AUTOSAR XML (schema 4-2-2)
package /STELLANTIS/EPT/COMSWCs
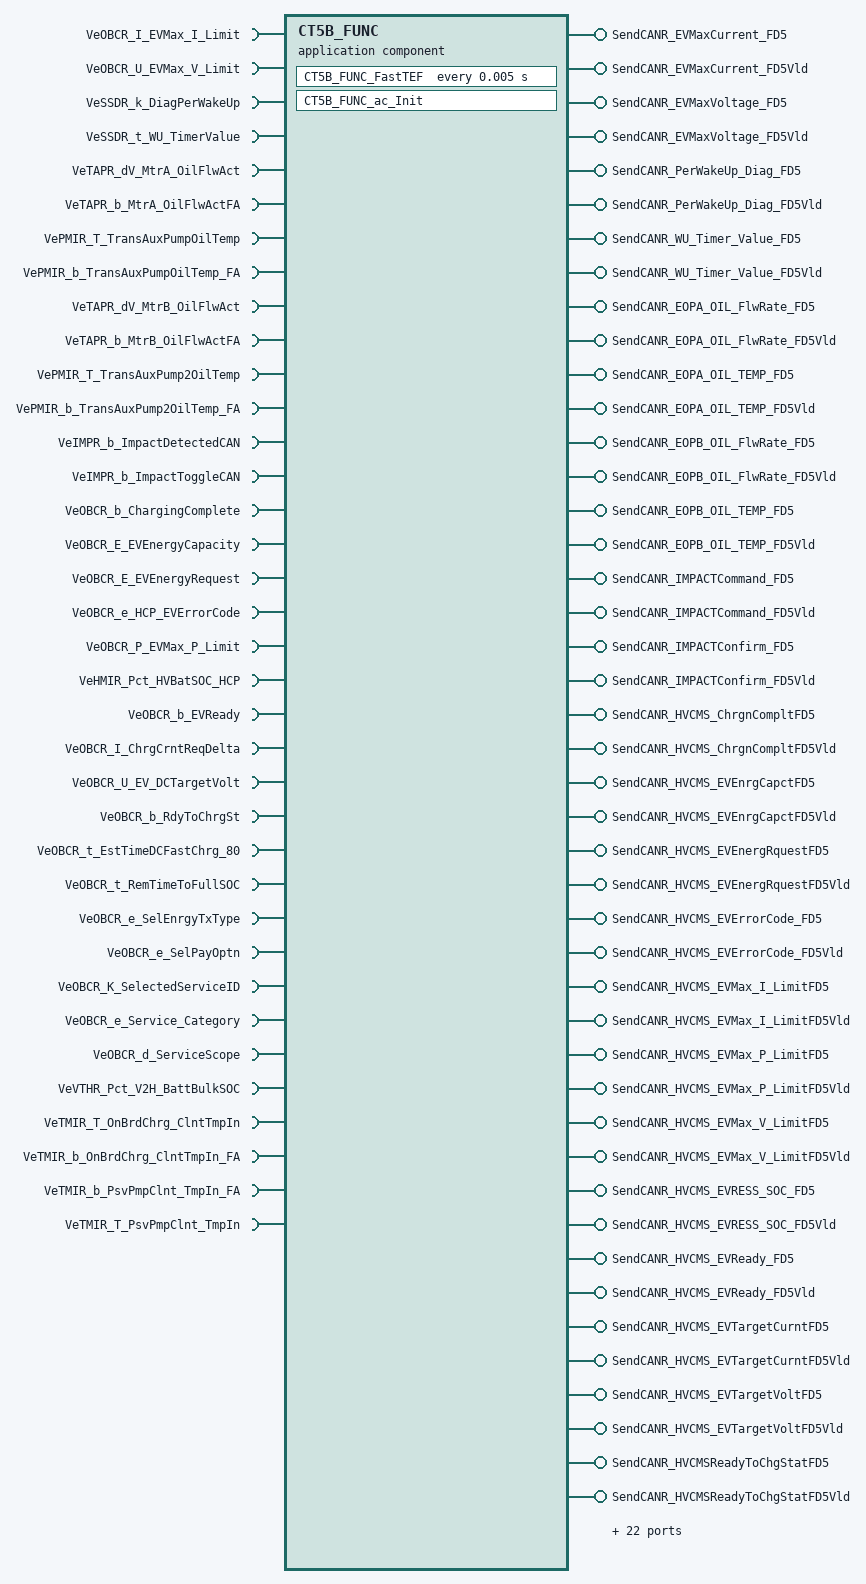
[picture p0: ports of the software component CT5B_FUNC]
  application sw component type CT5B_FUNC
    36 x require port:
      VeOBCR_I_EVMax_I_Limit: nonqueued-receiver-com-spec{data-element=Value, init-value=0}, required-interface=VeOBCR_I_EVMax_I_Limit
      VeOBCR_U_EVMax_V_Limit: nonqueued-receiver-com-spec{data-element=Value, init-value=0}, required-interface=VeOBCR_U_EVMax_V_Limit
      VeSSDR_k_DiagPerWakeUp: nonqueued-receiver-com-spec{data-element=Value, init-value=0}, required-interface=VeSSDR_k_DiagPerWakeUp
      VeSSDR_t_WU_TimerValue: nonqueued-receiver-com-spec{data-element=Value, init-value=0}, required-interface=VeSSDR_t_WU_TimerValue
      VeTAPR_dV_MtrA_OilFlwAct: nonqueued-receiver-com-spec{data-element=Value, init-value=0}, required-interface=VeTAPR_dV_MtrA_OilFlwAct
      VeTAPR_b_MtrA_OilFlwActFA: nonqueued-receiver-com-spec{data-element=Value, init-value=0}, required-interface=VeTAPR_b_MtrA_OilFlwActFA
      VePMIR_T_TransAuxPumpOilTemp: nonqueued-receiver-com-spec{data-element=Value, init-value=0}, required-interface=VePMIR_T_TransAuxPumpOilTemp
      VePMIR_b_TransAuxPumpOilTemp_FA: nonqueued-receiver-com-spec{data-element=Value, init-value=0}, required-interface=VePMIR_b_TransAuxPumpOilTemp_FA
      VeTAPR_dV_MtrB_OilFlwAct: nonqueued-receiver-com-spec{data-element=Value, init-value=0}, required-interface=VeTAPR_dV_MtrB_OilFlwAct
      VeTAPR_b_MtrB_OilFlwActFA: nonqueued-receiver-com-spec{data-element=Value, init-value=0}, required-interface=VeTAPR_b_MtrB_OilFlwActFA
      VePMIR_T_TransAuxPump2OilTemp: nonqueued-receiver-com-spec{data-element=Value, init-value=0}, required-interface=VePMIR_T_TransAuxPump2OilTemp
      VePMIR_b_TransAuxPump2OilTemp_FA: nonqueued-receiver-com-spec{data-element=Value, init-value=0}, required-interface=VePMIR_b_TransAuxPump2OilTemp_FA
      VeIMPR_b_ImpactDetectedCAN: nonqueued-receiver-com-spec{data-element=Value, init-value=0}, required-interface=VeIMPR_b_ImpactDetectedCAN
      VeIMPR_b_ImpactToggleCAN: nonqueued-receiver-com-spec{data-element=Value, init-value=0}, required-interface=VeIMPR_b_ImpactToggleCAN
      VeOBCR_b_ChargingComplete: nonqueued-receiver-com-spec{data-element=Value, init-value=0}, required-interface=VeOBCR_b_ChargingComplete
      VeOBCR_E_EVEnergyCapacity: nonqueued-receiver-com-spec{data-element=Value, init-value=0}, required-interface=VeOBCR_E_EVEnergyCapacity
      VeOBCR_E_EVEnergyRequest: nonqueued-receiver-com-spec{data-element=Value, init-value=0}, required-interface=VeOBCR_E_EVEnergyRequest
      VeOBCR_e_HCP_EVErrorCode: nonqueued-receiver-com-spec{data-element=Value, init-value=0}, required-interface=VeOBCR_e_HCP_EVErrorCode
      VeOBCR_P_EVMax_P_Limit: nonqueued-receiver-com-spec{data-element=Value, init-value=0}, required-interface=VeOBCR_P_EVMax_P_Limit
      VeHMIR_Pct_HVBatSOC_HCP: nonqueued-receiver-com-spec{data-element=Value, init-value=0}, required-interface=VeHMIR_Pct_HVBatSOC_HCP
      VeOBCR_b_EVReady: nonqueued-receiver-com-spec{data-element=Value, init-value=0}, required-interface=VeOBCR_b_EVReady
      VeOBCR_I_ChrgCrntReqDelta: nonqueued-receiver-com-spec{data-element=Value, init-value=0}, required-interface=VeOBCR_I_ChrgCrntReqDelta
      VeOBCR_U_EV_DCTargetVolt: nonqueued-receiver-com-spec{data-element=Value, init-value=0}, required-interface=VeOBCR_U_EV_DCTargetVolt
      VeOBCR_b_RdyToChrgSt: nonqueued-receiver-com-spec{data-element=Value, init-value=0}, required-interface=VeOBCR_b_RdyToChrgSt
      VeOBCR_t_EstTimeDCFastChrg_80: nonqueued-receiver-com-spec{data-element=Value, init-value=0}, required-interface=VeOBCR_t_EstTimeDCFastChrg_80
      VeOBCR_t_RemTimeToFullSOC: nonqueued-receiver-com-spec{data-element=Value, init-value=0}, required-interface=VeOBCR_t_RemTimeToFullSOC
      VeOBCR_e_SelEnrgyTxType: nonqueued-receiver-com-spec{data-element=Value, init-value=0}, required-interface=VeOBCR_e_SelEnrgyTxType
      VeOBCR_e_SelPayOptn: nonqueued-receiver-com-spec{data-element=Value, init-value=CeOBCR_e_NoPaymentSel}, required-interface=VeOBCR_e_SelPayOptn
      VeOBCR_K_SelectedServiceID: nonqueued-receiver-com-spec{data-element=Value, init-value=0}, required-interface=VeOBCR_K_SelectedServiceID
      VeOBCR_e_Service_Category: nonqueued-receiver-com-spec{data-element=Value, init-value=0}, required-interface=VeOBCR_e_Service_Category
      VeOBCR_d_ServiceScope: variation-point={short-label=vpVeOBCR_d_ServiceScope, sw-syscond=1}, nonqueued-receiver-com-spec{data-element=Value, init-value=0}, required-interface=VeOBCR_d_ServiceScope
      VeVTHR_Pct_V2H_BattBulkSOC: variation-point={short-label=vpVeVTHR_Pct_V2H_BattBulkSOC, sw-syscond=1}, nonqueued-receiver-com-spec{data-element=Value, init-value=0}, required-interface=VeVTHR_Pct_V2H_BattBulkSOC
      VeTMIR_T_OnBrdChrg_ClntTmpIn: nonqueued-receiver-com-spec{data-element=Value, init-value=0}, required-interface=VeTMIR_T_OnBrdChrg_ClntTmpIn
      VeTMIR_b_OnBrdChrg_ClntTmpIn_FA: nonqueued-receiver-com-spec{data-element=Value, init-value=0}, required-interface=VeTMIR_b_OnBrdChrg_ClntTmpIn_FA
      VeTMIR_b_PsvPmpClnt_TmpIn_FA: nonqueued-receiver-com-spec{data-element=Value, init-value=0}, required-interface=VeTMIR_b_PsvPmpClnt_TmpIn_FA
      VeTMIR_T_PsvPmpClnt_TmpIn: nonqueued-receiver-com-spec{data-element=Value, init-value=0}, required-interface=VeTMIR_T_PsvPmpClnt_TmpIn
    66 x provide port:
      SendCANR_EVMaxCurrent_FD5: nonqueued-sender-com-spec{data-element=SendCANR_EVMaxCurrent_FD5, init-value=0}, provided-interface=SendCANR_EVMaxCurrent_FD5
      SendCANR_EVMaxCurrent_FD5Vld: nonqueued-sender-com-spec{data-element=SendCANR_EVMaxCurrent_FD5Vld, init-value=0}, provided-interface=SendCANR_EVMaxCurrent_FD5Vld
      SendCANR_EVMaxVoltage_FD5: nonqueued-sender-com-spec{data-element=SendCANR_EVMaxVoltage_FD5, init-value=0}, provided-interface=SendCANR_EVMaxVoltage_FD5
      SendCANR_EVMaxVoltage_FD5Vld: nonqueued-sender-com-spec{data-element=SendCANR_EVMaxVoltage_FD5Vld, init-value=0}, provided-interface=SendCANR_EVMaxVoltage_FD5Vld
      SendCANR_PerWakeUp_Diag_FD5: nonqueued-sender-com-spec{data-element=SendCANR_PerWakeUp_Diag_FD5, init-value=0}, provided-interface=SendCANR_PerWakeUp_Diag_FD5
      SendCANR_PerWakeUp_Diag_FD5Vld: nonqueued-sender-com-spec{data-element=SendCANR_PerWakeUp_Diag_FD5Vld, init-value=0}, provided-interface=SendCANR_PerWakeUp_Diag_FD5Vld
      SendCANR_WU_Timer_Value_FD5: nonqueued-sender-com-spec{data-element=SendCANR_WU_Timer_Value_FD5, init-value=0}, provided-interface=SendCANR_WU_Timer_Value_FD5
      SendCANR_WU_Timer_Value_FD5Vld: nonqueued-sender-com-spec{data-element=SendCANR_WU_Timer_Value_FD5Vld, init-value=0}, provided-interface=SendCANR_WU_Timer_Value_FD5Vld
      SendCANR_EOPA_OIL_FlwRate_FD5: nonqueued-sender-com-spec{data-element=SendCANR_EOPA_OIL_FlwRate_FD5, init-value=0}, provided-interface=SendCANR_EOPA_OIL_FlwRate_FD5
      SendCANR_EOPA_OIL_FlwRate_FD5Vld: nonqueued-sender-com-spec{data-element=SendCANR_EOPA_OIL_FlwRate_FD5Vld, init-value=0}, provided-interface=SendCANR_EOPA_OIL_FlwRate_FD5Vld
      SendCANR_EOPA_OIL_TEMP_FD5: nonqueued-sender-com-spec{data-element=SendCANR_EOPA_OIL_TEMP_FD5, init-value=0}, provided-interface=SendCANR_EOPA_OIL_TEMP_FD5
      SendCANR_EOPA_OIL_TEMP_FD5Vld: nonqueued-sender-com-spec{data-element=SendCANR_EOPA_OIL_TEMP_FD5Vld, init-value=0}, provided-interface=SendCANR_EOPA_OIL_TEMP_FD5Vld
      SendCANR_EOPB_OIL_FlwRate_FD5: nonqueued-sender-com-spec{data-element=SendCANR_EOPB_OIL_FlwRate_FD5, init-value=0}, provided-interface=SendCANR_EOPB_OIL_FlwRate_FD5
      SendCANR_EOPB_OIL_FlwRate_FD5Vld: nonqueued-sender-com-spec{data-element=SendCANR_EOPB_OIL_FlwRate_FD5Vld, init-value=0}, provided-interface=SendCANR_EOPB_OIL_FlwRate_FD5Vld
      SendCANR_EOPB_OIL_TEMP_FD5: nonqueued-sender-com-spec{data-element=SendCANR_EOPB_OIL_TEMP_FD5, init-value=0}, provided-interface=SendCANR_EOPB_OIL_TEMP_FD5
      SendCANR_EOPB_OIL_TEMP_FD5Vld: nonqueued-sender-com-spec{data-element=SendCANR_EOPB_OIL_TEMP_FD5Vld, init-value=0}, provided-interface=SendCANR_EOPB_OIL_TEMP_FD5Vld
      SendCANR_IMPACTCommand_FD5: nonqueued-sender-com-spec{data-element=SendCANR_IMPACTCommand_FD5, init-value=0}, provided-interface=SendCANR_IMPACTCommand_FD5
      SendCANR_IMPACTCommand_FD5Vld: nonqueued-sender-com-spec{data-element=SendCANR_IMPACTCommand_FD5Vld, init-value=0}, provided-interface=SendCANR_IMPACTCommand_FD5Vld
      SendCANR_IMPACTConfirm_FD5: nonqueued-sender-com-spec{data-element=SendCANR_IMPACTConfirm_FD5, init-value=0}, provided-interface=SendCANR_IMPACTConfirm_FD5
      SendCANR_IMPACTConfirm_FD5Vld: nonqueued-sender-com-spec{data-element=SendCANR_IMPACTConfirm_FD5Vld, init-value=0}, provided-interface=SendCANR_IMPACTConfirm_FD5Vld
      SendCANR_HVCMS_ChrgnCompltFD5: nonqueued-sender-com-spec{data-element=SendCANR_HVCMS_ChrgnCompltFD5, init-value=0}, provided-interface=SendCANR_HVCMS_ChrgnCompltFD5
      SendCANR_HVCMS_ChrgnCompltFD5Vld: nonqueued-sender-com-spec{data-element=SendCANR_HVCMS_ChrgnCompltFD5Vld, init-value=0}, provided-interface=SendCANR_HVCMS_ChrgnCompltFD5Vld
      SendCANR_HVCMS_EVEnrgCapctFD5: nonqueued-sender-com-spec{data-element=SendCANR_HVCMS_EVEnrgCapctFD5, init-value=0}, provided-interface=SendCANR_HVCMS_EVEnrgCapctFD5
      SendCANR_HVCMS_EVEnrgCapctFD5Vld: nonqueued-sender-com-spec{data-element=SendCANR_HVCMS_EVEnrgCapctFD5Vld, init-value=0}, provided-interface=SendCANR_HVCMS_EVEnrgCapctFD5Vld
      SendCANR_HVCMS_EVEnergRquestFD5: nonqueued-sender-com-spec{data-element=SendCANR_HVCMS_EVEnergRquestFD5, init-value=0}, provided-interface=SendCANR_HVCMS_EVEnergRquestFD5
      SendCANR_HVCMS_EVEnergRquestFD5Vld: nonqueued-sender-com-spec{data-element=SendCANR_HVCMS_EVEnergRquestFD5Vld, init-value=0}, provided-interface=SendCANR_HVCMS_EVEnergRquestFD5Vld
      SendCANR_HVCMS_EVErrorCode_FD5: nonqueued-sender-com-spec{data-element=SendCANR_HVCMS_EVErrorCode_FD5, init-value=0}, provided-interface=SendCANR_HVCMS_EVErrorCode_FD5
      SendCANR_HVCMS_EVErrorCode_FD5Vld: nonqueued-sender-com-spec{data-element=SendCANR_HVCMS_EVErrorCode_FD5Vld, init-value=0}, provided-interface=SendCANR_HVCMS_EVErrorCode_FD5Vld
      SendCANR_HVCMS_EVMax_I_LimitFD5: nonqueued-sender-com-spec{data-element=SendCANR_HVCMS_EVMax_I_LimitFD5, init-value=0}, provided-interface=SendCANR_HVCMS_EVMax_I_LimitFD5
      SendCANR_HVCMS_EVMax_I_LimitFD5Vld: nonqueued-sender-com-spec{data-element=SendCANR_HVCMS_EVMax_I_LimitFD5Vld, init-value=0}, provided-interface=SendCANR_HVCMS_EVMax_I_LimitFD5Vld
      SendCANR_HVCMS_EVMax_P_LimitFD5: nonqueued-sender-com-spec{data-element=SendCANR_HVCMS_EVMax_P_LimitFD5, init-value=0}, provided-interface=SendCANR_HVCMS_EVMax_P_LimitFD5
      SendCANR_HVCMS_EVMax_P_LimitFD5Vld: nonqueued-sender-com-spec{data-element=SendCANR_HVCMS_EVMax_P_LimitFD5Vld, init-value=0}, provided-interface=SendCANR_HVCMS_EVMax_P_LimitFD5Vld
      SendCANR_HVCMS_EVMax_V_LimitFD5: nonqueued-sender-com-spec{data-element=SendCANR_HVCMS_EVMax_V_LimitFD5, init-value=0}, provided-interface=SendCANR_HVCMS_EVMax_V_LimitFD5
      SendCANR_HVCMS_EVMax_V_LimitFD5Vld: nonqueued-sender-com-spec{data-element=SendCANR_HVCMS_EVMax_V_LimitFD5Vld, init-value=0}, provided-interface=SendCANR_HVCMS_EVMax_V_LimitFD5Vld
      SendCANR_HVCMS_EVRESS_SOC_FD5: nonqueued-sender-com-spec{data-element=SendCANR_HVCMS_EVRESS_SOC_FD5, init-value=0}, provided-interface=SendCANR_HVCMS_EVRESS_SOC_FD5
      SendCANR_HVCMS_EVRESS_SOC_FD5Vld: nonqueued-sender-com-spec{data-element=SendCANR_HVCMS_EVRESS_SOC_FD5Vld, init-value=0}, provided-interface=SendCANR_HVCMS_EVRESS_SOC_FD5Vld
      SendCANR_HVCMS_EVReady_FD5: nonqueued-sender-com-spec{data-element=SendCANR_HVCMS_EVReady_FD5, init-value=0}, provided-interface=SendCANR_HVCMS_EVReady_FD5
      SendCANR_HVCMS_EVReady_FD5Vld: nonqueued-sender-com-spec{data-element=SendCANR_HVCMS_EVReady_FD5Vld, init-value=0}, provided-interface=SendCANR_HVCMS_EVReady_FD5Vld
      SendCANR_HVCMS_EVTargetCurntFD5: nonqueued-sender-com-spec{data-element=SendCANR_HVCMS_EVTargetCurntFD5, init-value=0}, provided-interface=SendCANR_HVCMS_EVTargetCurntFD5
      SendCANR_HVCMS_EVTargetCurntFD5Vld: nonqueued-sender-com-spec{data-element=SendCANR_HVCMS_EVTargetCurntFD5Vld, init-value=0}, provided-interface=SendCANR_HVCMS_EVTargetCurntFD5Vld
      SendCANR_HVCMS_EVTargetVoltFD5: nonqueued-sender-com-spec{data-element=SendCANR_HVCMS_EVTargetVoltFD5, init-value=0}, provided-interface=SendCANR_HVCMS_EVTargetVoltFD5
      SendCANR_HVCMS_EVTargetVoltFD5Vld: nonqueued-sender-com-spec{data-element=SendCANR_HVCMS_EVTargetVoltFD5Vld, init-value=0}, provided-interface=SendCANR_HVCMS_EVTargetVoltFD5Vld
      SendCANR_HVCMSReadyToChgStatFD5: nonqueued-sender-com-spec{data-element=SendCANR_HVCMSReadyToChgStatFD5, init-value=0}, provided-interface=SendCANR_HVCMSReadyToChgStatFD5
      SendCANR_HVCMSReadyToChgStatFD5Vld: nonqueued-sender-com-spec{data-element=SendCANR_HVCMSReadyToChgStatFD5Vld, init-value=0}, provided-interface=SendCANR_HVCMSReadyToChgStatFD5Vld
      SendCANR_HVCMSRemTimToBlkSOCFD5: nonqueued-sender-com-spec{data-element=SendCANR_HVCMSRemTimToBlkSOCFD5, init-value=0}, provided-interface=SendCANR_HVCMSRemTimToBlkSOCFD5
      SendCANR_HVCMSRemTimToBlkSOCFD5Vld: nonqueued-sender-com-spec{data-element=SendCANR_HVCMSRemTimToBlkSOCFD5Vld, init-value=0}, provided-interface=SendCANR_HVCMSRemTimToBlkSOCFD5Vld
      SendCANR_HVCMSRemTimToFulSOCFD5: nonqueued-sender-com-spec{data-element=SendCANR_HVCMSRemTimToFulSOCFD5, init-value=0}, provided-interface=SendCANR_HVCMSRemTimToFulSOCFD5
      SendCANR_HVCMSRemTimToFulSOCFD5Vld: nonqueued-sender-com-spec{data-element=SendCANR_HVCMSRemTimToFulSOCFD5Vld, init-value=0}, provided-interface=SendCANR_HVCMSRemTimToFulSOCFD5Vld
      SendCANR_HVCMSSlfEnrgTrnfTypFD5: nonqueued-sender-com-spec{data-element=SendCANR_HVCMSSlfEnrgTrnfTypFD5, init-value=0}, provided-interface=SendCANR_HVCMSSlfEnrgTrnfTypFD5
      SendCANR_HVCMSSlfEnrgTrnfTypFD5Vld: nonqueued-sender-com-spec{data-element=SendCANR_HVCMSSlfEnrgTrnfTypFD5Vld, init-value=0}, provided-interface=SendCANR_HVCMSSlfEnrgTrnfTypFD5Vld
      SendCANR_HVCMS_SeldPymntOptnFD5: nonqueued-sender-com-spec{data-element=SendCANR_HVCMS_SeldPymntOptnFD5, init-value=0}, provided-interface=SendCANR_HVCMS_SeldPymntOptnFD5
      SendCANR_HVCMS_SeldPymntOptnFD5Vld: nonqueued-sender-com-spec{data-element=SendCANR_HVCMS_SeldPymntOptnFD5Vld, init-value=0}, provided-interface=SendCANR_HVCMS_SeldPymntOptnFD5Vld
      SendCANR_HVCMSSelectedServIdFD5: nonqueued-sender-com-spec{data-element=SendCANR_HVCMSSelectedServIdFD5, init-value=0}, provided-interface=SendCANR_HVCMSSelectedServIdFD5
      SendCANR_HVCMSSelectedServIdFD5Vld: nonqueued-sender-com-spec{data-element=SendCANR_HVCMSSelectedServIdFD5Vld, init-value=0}, provided-interface=SendCANR_HVCMSSelectedServIdFD5Vld
      SendCANR_HVCMSServiceCatgoryFD5: nonqueued-sender-com-spec{data-element=SendCANR_HVCMSServiceCatgoryFD5, init-value=0}, provided-interface=SendCANR_HVCMSServiceCatgoryFD5
      SendCANR_HVCMSServiceCatgoryFD5Vld: nonqueued-sender-com-spec{data-element=SendCANR_HVCMSServiceCatgoryFD5Vld, init-value=0}, provided-interface=SendCANR_HVCMSServiceCatgoryFD5Vld
      SendCANR_HVCMS_ServiceScope_FD5: variation-point={short-label=vpSendCANR_HVCMS_ServiceScope_FD5, sw-syscond=1}, nonqueued-sender-com-spec{data-element=SendCANR_HVCMS_ServiceScope_FD5, init-value=0}, provided-interface=SendCANR_HVCMS_ServiceScope_FD5
      SendCANR_HVCMS_ServiceScope_FD5Vld: variation-point={short-label=vpSendCANR_HVCMS_ServiceScope_FD5Vld, sw-syscond=1}, nonqueued-sender-com-spec{data-element=SendCANR_HVCMS_ServiceScope_FD5Vld, init-value=0}, provided-interface=SendCANR_HVCMS_ServiceScope_FD5Vld
      SendCANR_VDCM_BattBulkSOC_FD5: variation-point={short-label=vpSendCANR_VDCM_BattBulkSOC_FD5, sw-syscond=1}, nonqueued-sender-com-spec{data-element=SendCANR_VDCM_BattBulkSOC_FD5, init-value=0}, provided-interface=SendCANR_VDCM_BattBulkSOC_FD5
      SendCANR_VDCM_BattBulkSOC_FD5Vld: variation-point={short-label=vpSendCANR_VDCM_BattBulkSOC_FD5Vld, sw-syscond=1}, nonqueued-sender-com-spec{data-element=SendCANR_VDCM_BattBulkSOC_FD5Vld, init-value=0}, provided-interface=SendCANR_VDCM_BattBulkSOC_FD5Vld
      SendCANR_T4_Sensor_Temp_FD5: nonqueued-sender-com-spec{data-element=SendCANR_T4_Sensor_Temp_FD5, init-value=0}, provided-interface=SendCANR_T4_Sensor_Temp_FD5
      SendCANR_T4_Sensor_Temp_FD5Vld: nonqueued-sender-com-spec{data-element=SendCANR_T4_Sensor_Temp_FD5Vld, init-value=0}, provided-interface=SendCANR_T4_Sensor_Temp_FD5Vld
      SendCANR_T7_CoolantTmpVldty_FD5: nonqueued-sender-com-spec{data-element=SendCANR_T7_CoolantTmpVldty_FD5, init-value=0}, provided-interface=SendCANR_T7_CoolantTmpVldty_FD5
      SendCANR_T7_CoolantTmpVldty_FD5Vld: nonqueued-sender-com-spec{data-element=SendCANR_T7_CoolantTmpVldty_FD5Vld, init-value=0}, provided-interface=SendCANR_T7_CoolantTmpVldty_FD5Vld
      SendCANR_T7_Sensor_Temp_FD5: nonqueued-sender-com-spec{data-element=SendCANR_T7_Sensor_Temp_FD5, init-value=0}, provided-interface=SendCANR_T7_Sensor_Temp_FD5
      SendCANR_T7_Sensor_Temp_FD5Vld: nonqueued-sender-com-spec{data-element=SendCANR_T7_Sensor_Temp_FD5Vld, init-value=0}, provided-interface=SendCANR_T7_Sensor_Temp_FD5Vld
    behavior IB_CT5B_FUNC: data-type-mapping=[msADTtoIDTMapping, ADTtoIDTMapping], handle-termination-and-restart=NO-SUPPORT
      timing event Event_FastTEF: start-on-event=CT5B_FUNC_FastTEF, period=0.005
      init event Event_CT5B_FUNC_ac_Init: start-on-event=CT5B_FUNC_ac_Init
      runnable CT5B_FUNC_ac_Init
      runnable CT5B_FUNC_FastTEF
        data-receive-point-by-arguments:
          36 x access:
            IN_VeHMIR_Pct_HVBatSOC_HCP_Value: accessed-variable=VeHMIR_Pct_HVBatSOC_HCP.Value
            IN_VeIMPR_b_ImpactDetectedCAN_Value: accessed-variable=VeIMPR_b_ImpactDetectedCAN.Value
            IN_VeIMPR_b_ImpactToggleCAN_Value: accessed-variable=VeIMPR_b_ImpactToggleCAN.Value
            IN_VeOBCR_E_EVEnergyCapacity_Value: accessed-variable=VeOBCR_E_EVEnergyCapacity.Value
            IN_VeOBCR_E_EVEnergyRequest_Value: accessed-variable=VeOBCR_E_EVEnergyRequest.Value
            IN_VeOBCR_I_ChrgCrntReqDelta_Value: accessed-variable=VeOBCR_I_ChrgCrntReqDelta.Value
            IN_VeOBCR_I_EVMax_I_Limit_Value: accessed-variable=VeOBCR_I_EVMax_I_Limit.Value
            IN_VeOBCR_K_SelectedServiceID_Value: accessed-variable=VeOBCR_K_SelectedServiceID.Value
            IN_VeOBCR_P_EVMax_P_Limit_Value: accessed-variable=VeOBCR_P_EVMax_P_Limit.Value
            IN_VeOBCR_U_EVMax_V_Limit_Value: accessed-variable=VeOBCR_U_EVMax_V_Limit.Value
            IN_VeOBCR_U_EV_DCTargetVolt_Value: accessed-variable=VeOBCR_U_EV_DCTargetVolt.Value
            IN_VeOBCR_b_ChargingComplete_Value: accessed-variable=VeOBCR_b_ChargingComplete.Value
            IN_VeOBCR_b_EVReady_Value: accessed-variable=VeOBCR_b_EVReady.Value
            IN_VeOBCR_b_RdyToChrgSt_Value: accessed-variable=VeOBCR_b_RdyToChrgSt.Value
            IN_VeOBCR_d_ServiceScope_Value: accessed-variable=VeOBCR_d_ServiceScope.Value, variation-point={short-label=vpIN_VeOBCR_d_ServiceScope_Value, sw-syscond=1}
            IN_VeOBCR_e_HCP_EVErrorCode_Value: accessed-variable=VeOBCR_e_HCP_EVErrorCode.Value
            IN_VeOBCR_e_SelEnrgyTxType_Value: accessed-variable=VeOBCR_e_SelEnrgyTxType.Value
            IN_VeOBCR_e_SelPayOptn_Value: accessed-variable=VeOBCR_e_SelPayOptn.Value
            IN_VeOBCR_e_Service_Category_Value: accessed-variable=VeOBCR_e_Service_Category.Value
            IN_VeOBCR_t_EstTimeDCFastChrg_80_Value: accessed-variable=VeOBCR_t_EstTimeDCFastChrg_80.Value
            IN_VeOBCR_t_RemTimeToFullSOC_Value: accessed-variable=VeOBCR_t_RemTimeToFullSOC.Value
            IN_VePMIR_T_TransAuxPump2OilTemp_Value: accessed-variable=VePMIR_T_TransAuxPump2OilTemp.Value
            IN_VePMIR_T_TransAuxPumpOilTemp_Value: accessed-variable=VePMIR_T_TransAuxPumpOilTemp.Value
            IN_VePMIR_b_TransAuxPump2OilTemp_FA_Value: accessed-variable=VePMIR_b_TransAuxPump2OilTemp_FA.Value
            IN_VePMIR_b_TransAuxPumpOilTemp_FA_Value: accessed-variable=VePMIR_b_TransAuxPumpOilTemp_FA.Value
            IN_VeSSDR_k_DiagPerWakeUp_Value: accessed-variable=VeSSDR_k_DiagPerWakeUp.Value
            IN_VeSSDR_t_WU_TimerValue_Value: accessed-variable=VeSSDR_t_WU_TimerValue.Value
            IN_VeTAPR_b_MtrA_OilFlwActFA_Value: accessed-variable=VeTAPR_b_MtrA_OilFlwActFA.Value
            IN_VeTAPR_b_MtrB_OilFlwActFA_Value: accessed-variable=VeTAPR_b_MtrB_OilFlwActFA.Value
            IN_VeTAPR_dV_MtrA_OilFlwAct_Value: accessed-variable=VeTAPR_dV_MtrA_OilFlwAct.Value
            IN_VeTAPR_dV_MtrB_OilFlwAct_Value: accessed-variable=VeTAPR_dV_MtrB_OilFlwAct.Value
            IN_VeTMIR_T_OnBrdChrg_ClntTmpIn_Value: accessed-variable=VeTMIR_T_OnBrdChrg_ClntTmpIn.Value
            IN_VeTMIR_T_PsvPmpClnt_TmpIn_Value: accessed-variable=VeTMIR_T_PsvPmpClnt_TmpIn.Value
            IN_VeTMIR_b_OnBrdChrg_ClntTmpIn_FA_Value: accessed-variable=VeTMIR_b_OnBrdChrg_ClntTmpIn_FA.Value
            IN_VeTMIR_b_PsvPmpClnt_TmpIn_FA_Value: accessed-variable=VeTMIR_b_PsvPmpClnt_TmpIn_FA.Value
            IN_VeVTHR_Pct_V2H_BattBulkSOC_Value: accessed-variable=VeVTHR_Pct_V2H_BattBulkSOC.Value, variation-point={short-label=vpIN_VeVTHR_Pct_V2H_BattBulkSOC_Value, sw-syscond=1}
        data-send-points:
          66 x access:
            OUT_SendCANR_EVMaxCurrent_FD5_SendCANR_EVMaxCurrent_FD5: accessed-variable=SendCANR_EVMaxCurrent_FD5.SendCANR_EVMaxCurrent_FD5
            OUT_SendCANR_EVMaxCurrent_FD5Vld_SendCANR_EVMaxCurrent_FD5Vld: accessed-variable=SendCANR_EVMaxCurrent_FD5Vld.SendCANR_EVMaxCurrent_FD5Vld
            OUT_SendCANR_EVMaxVoltage_FD5_SendCANR_EVMaxVoltage_FD5: accessed-variable=SendCANR_EVMaxVoltage_FD5.SendCANR_EVMaxVoltage_FD5
            OUT_SendCANR_EVMaxVoltage_FD5Vld_SendCANR_EVMaxVoltage_FD5Vld: accessed-variable=SendCANR_EVMaxVoltage_FD5Vld.SendCANR_EVMaxVoltage_FD5Vld
            OUT_SendCANR_PerWakeUp_Diag_FD5_SendCANR_PerWakeUp_Diag_FD5: accessed-variable=SendCANR_PerWakeUp_Diag_FD5.SendCANR_PerWakeUp_Diag_FD5
            OUT_SendCANR_PerWakeUp_Diag_FD5Vld_SendCANR_PerWakeUp_Diag_FD5Vld: accessed-variable=SendCANR_PerWakeUp_Diag_FD5Vld.SendCANR_PerWakeUp_Diag_FD5Vld
            OUT_SendCANR_WU_Timer_Value_FD5_SendCANR_WU_Timer_Value_FD5: accessed-variable=SendCANR_WU_Timer_Value_FD5.SendCANR_WU_Timer_Value_FD5
            OUT_SendCANR_WU_Timer_Value_FD5Vld_SendCANR_WU_Timer_Value_FD5Vld: accessed-variable=SendCANR_WU_Timer_Value_FD5Vld.SendCANR_WU_Timer_Value_FD5Vld
            OUT_SendCANR_EOPA_OIL_FlwRate_FD5_SendCANR_EOPA_OIL_FlwRate_FD5: accessed-variable=SendCANR_EOPA_OIL_FlwRate_FD5.SendCANR_EOPA_OIL_FlwRate_FD5
            OUT_SendCANR_EOPA_OIL_FlwRate_FD5Vld_SendCANR_EOPA_OIL_FlwRate_FD5Vld: accessed-variable=SendCANR_EOPA_OIL_FlwRate_FD5Vld.SendCANR_EOPA_OIL_FlwRate_FD5Vld
            OUT_SendCANR_EOPA_OIL_TEMP_FD5_SendCANR_EOPA_OIL_TEMP_FD5: accessed-variable=SendCANR_EOPA_OIL_TEMP_FD5.SendCANR_EOPA_OIL_TEMP_FD5
            OUT_SendCANR_EOPA_OIL_TEMP_FD5Vld_SendCANR_EOPA_OIL_TEMP_FD5Vld: accessed-variable=SendCANR_EOPA_OIL_TEMP_FD5Vld.SendCANR_EOPA_OIL_TEMP_FD5Vld
            OUT_SendCANR_EOPB_OIL_FlwRate_FD5_SendCANR_EOPB_OIL_FlwRate_FD5: accessed-variable=SendCANR_EOPB_OIL_FlwRate_FD5.SendCANR_EOPB_OIL_FlwRate_FD5
            OUT_SendCANR_EOPB_OIL_FlwRate_FD5Vld_SendCANR_EOPB_OIL_FlwRate_FD5Vld: accessed-variable=SendCANR_EOPB_OIL_FlwRate_FD5Vld.SendCANR_EOPB_OIL_FlwRate_FD5Vld
            OUT_SendCANR_EOPB_OIL_TEMP_FD5_SendCANR_EOPB_OIL_TEMP_FD5: accessed-variable=SendCANR_EOPB_OIL_TEMP_FD5.SendCANR_EOPB_OIL_TEMP_FD5
            OUT_SendCANR_EOPB_OIL_TEMP_FD5Vld_SendCANR_EOPB_OIL_TEMP_FD5Vld: accessed-variable=SendCANR_EOPB_OIL_TEMP_FD5Vld.SendCANR_EOPB_OIL_TEMP_FD5Vld
            OUT_SendCANR_IMPACTCommand_FD5_SendCANR_IMPACTCommand_FD5: accessed-variable=SendCANR_IMPACTCommand_FD5.SendCANR_IMPACTCommand_FD5
            OUT_SendCANR_IMPACTCommand_FD5Vld_SendCANR_IMPACTCommand_FD5Vld: accessed-variable=SendCANR_IMPACTCommand_FD5Vld.SendCANR_IMPACTCommand_FD5Vld
            OUT_SendCANR_IMPACTConfirm_FD5_SendCANR_IMPACTConfirm_FD5: accessed-variable=SendCANR_IMPACTConfirm_FD5.SendCANR_IMPACTConfirm_FD5
            OUT_SendCANR_IMPACTConfirm_FD5Vld_SendCANR_IMPACTConfirm_FD5Vld: accessed-variable=SendCANR_IMPACTConfirm_FD5Vld.SendCANR_IMPACTConfirm_FD5Vld
            OUT_SendCANR_HVCMS_ChrgnCompltFD5_SendCANR_HVCMS_ChrgnCompltFD5: accessed-variable=SendCANR_HVCMS_ChrgnCompltFD5.SendCANR_HVCMS_ChrgnCompltFD5
            OUT_SendCANR_HVCMS_ChrgnCompltFD5Vld_SendCANR_HVCMS_ChrgnCompltFD5Vld: accessed-variable=SendCANR_HVCMS_ChrgnCompltFD5Vld.SendCANR_HVCMS_ChrgnCompltFD5Vld
            OUT_SendCANR_HVCMS_EVEnrgCapctFD5_SendCANR_HVCMS_EVEnrgCapctFD5: accessed-variable=SendCANR_HVCMS_EVEnrgCapctFD5.SendCANR_HVCMS_EVEnrgCapctFD5
            OUT_SendCANR_HVCMS_EVEnrgCapctFD5Vld_SendCANR_HVCMS_EVEnrgCapctFD5Vld: accessed-variable=SendCANR_HVCMS_EVEnrgCapctFD5Vld.SendCANR_HVCMS_EVEnrgCapctFD5Vld
            OUT_SendCANR_HVCMS_EVEnergRquestFD5_SendCANR_HVCMS_EVEnergRquestFD5: accessed-variable=SendCANR_HVCMS_EVEnergRquestFD5.SendCANR_HVCMS_EVEnergRquestFD5
            OUT_SendCANR_HVCMS_EVEnergRquestFD5Vld_SendCANR_HVCMS_EVEnergRquestFD5Vld: accessed-variable=SendCANR_HVCMS_EVEnergRquestFD5Vld.SendCANR_HVCMS_EVEnergRquestFD5Vld
            OUT_SendCANR_HVCMS_EVErrorCode_FD5_SendCANR_HVCMS_EVErrorCode_FD5: accessed-variable=SendCANR_HVCMS_EVErrorCode_FD5.SendCANR_HVCMS_EVErrorCode_FD5
            OUT_SendCANR_HVCMS_EVErrorCode_FD5Vld_SendCANR_HVCMS_EVErrorCode_FD5Vld: accessed-variable=SendCANR_HVCMS_EVErrorCode_FD5Vld.SendCANR_HVCMS_EVErrorCode_FD5Vld
            OUT_SendCANR_HVCMS_EVMax_I_LimitFD5_SendCANR_HVCMS_EVMax_I_LimitFD5: accessed-variable=SendCANR_HVCMS_EVMax_I_LimitFD5.SendCANR_HVCMS_EVMax_I_LimitFD5
            OUT_SendCANR_HVCMS_EVMax_I_LimitFD5Vld_SendCANR_HVCMS_EVMax_I_LimitFD5Vld: accessed-variable=SendCANR_HVCMS_EVMax_I_LimitFD5Vld.SendCANR_HVCMS_EVMax_I_LimitFD5Vld
            OUT_SendCANR_HVCMS_EVMax_P_LimitFD5_SendCANR_HVCMS_EVMax_P_LimitFD5: accessed-variable=SendCANR_HVCMS_EVMax_P_LimitFD5.SendCANR_HVCMS_EVMax_P_LimitFD5
            OUT_SendCANR_HVCMS_EVMax_P_LimitFD5Vld_SendCANR_HVCMS_EVMax_P_LimitFD5Vld: accessed-variable=SendCANR_HVCMS_EVMax_P_LimitFD5Vld.SendCANR_HVCMS_EVMax_P_LimitFD5Vld
            OUT_SendCANR_HVCMS_EVMax_V_LimitFD5_SendCANR_HVCMS_EVMax_V_LimitFD5: accessed-variable=SendCANR_HVCMS_EVMax_V_LimitFD5.SendCANR_HVCMS_EVMax_V_LimitFD5
            OUT_SendCANR_HVCMS_EVMax_V_LimitFD5Vld_SendCANR_HVCMS_EVMax_V_LimitFD5Vld: accessed-variable=SendCANR_HVCMS_EVMax_V_LimitFD5Vld.SendCANR_HVCMS_EVMax_V_LimitFD5Vld
            OUT_SendCANR_HVCMS_EVRESS_SOC_FD5_SendCANR_HVCMS_EVRESS_SOC_FD5: accessed-variable=SendCANR_HVCMS_EVRESS_SOC_FD5.SendCANR_HVCMS_EVRESS_SOC_FD5
            OUT_SendCANR_HVCMS_EVRESS_SOC_FD5Vld_SendCANR_HVCMS_EVRESS_SOC_FD5Vld: accessed-variable=SendCANR_HVCMS_EVRESS_SOC_FD5Vld.SendCANR_HVCMS_EVRESS_SOC_FD5Vld
            OUT_SendCANR_HVCMS_EVReady_FD5_SendCANR_HVCMS_EVReady_FD5: accessed-variable=SendCANR_HVCMS_EVReady_FD5.SendCANR_HVCMS_EVReady_FD5
            OUT_SendCANR_HVCMS_EVReady_FD5Vld_SendCANR_HVCMS_EVReady_FD5Vld: accessed-variable=SendCANR_HVCMS_EVReady_FD5Vld.SendCANR_HVCMS_EVReady_FD5Vld
            OUT_SendCANR_HVCMS_EVTargetCurntFD5_SendCANR_HVCMS_EVTargetCurntFD5: accessed-variable=SendCANR_HVCMS_EVTargetCurntFD5.SendCANR_HVCMS_EVTargetCurntFD5
            OUT_SendCANR_HVCMS_EVTargetCurntFD5Vld_SendCANR_HVCMS_EVTargetCurntFD5Vld: accessed-variable=SendCANR_HVCMS_EVTargetCurntFD5Vld.SendCANR_HVCMS_EVTargetCurntFD5Vld
            OUT_SendCANR_HVCMS_EVTargetVoltFD5_SendCANR_HVCMS_EVTargetVoltFD5: accessed-variable=SendCANR_HVCMS_EVTargetVoltFD5.SendCANR_HVCMS_EVTargetVoltFD5
            OUT_SendCANR_HVCMS_EVTargetVoltFD5Vld_SendCANR_HVCMS_EVTargetVoltFD5Vld: accessed-variable=SendCANR_HVCMS_EVTargetVoltFD5Vld.SendCANR_HVCMS_EVTargetVoltFD5Vld
            OUT_SendCANR_HVCMSReadyToChgStatFD5_SendCANR_HVCMSReadyToChgStatFD5: accessed-variable=SendCANR_HVCMSReadyToChgStatFD5.SendCANR_HVCMSReadyToChgStatFD5
            OUT_SendCANR_HVCMSReadyToChgStatFD5Vld_SendCANR_HVCMSReadyToChgStatFD5Vld: accessed-variable=SendCANR_HVCMSReadyToChgStatFD5Vld.SendCANR_HVCMSReadyToChgStatFD5Vld
            OUT_SendCANR_HVCMSRemTimToBlkSOCFD5_SendCANR_HVCMSRemTimToBlkSOCFD5: accessed-variable=SendCANR_HVCMSRemTimToBlkSOCFD5.SendCANR_HVCMSRemTimToBlkSOCFD5
            OUT_SendCANR_HVCMSRemTimToBlkSOCFD5Vld_SendCANR_HVCMSRemTimToBlkSOCFD5Vld: accessed-variable=SendCANR_HVCMSRemTimToBlkSOCFD5Vld.SendCANR_HVCMSRemTimToBlkSOCFD5Vld
            OUT_SendCANR_HVCMSRemTimToFulSOCFD5_SendCANR_HVCMSRemTimToFulSOCFD5: accessed-variable=SendCANR_HVCMSRemTimToFulSOCFD5.SendCANR_HVCMSRemTimToFulSOCFD5
            OUT_SendCANR_HVCMSRemTimToFulSOCFD5Vld_SendCANR_HVCMSRemTimToFulSOCFD5Vld: accessed-variable=SendCANR_HVCMSRemTimToFulSOCFD5Vld.SendCANR_HVCMSRemTimToFulSOCFD5Vld
            OUT_SendCANR_HVCMSSlfEnrgTrnfTypFD5_SendCANR_HVCMSSlfEnrgTrnfTypFD5: accessed-variable=SendCANR_HVCMSSlfEnrgTrnfTypFD5.SendCANR_HVCMSSlfEnrgTrnfTypFD5
            OUT_SendCANR_HVCMSSlfEnrgTrnfTypFD5Vld_SendCANR_HVCMSSlfEnrgTrnfTypFD5Vld: accessed-variable=SendCANR_HVCMSSlfEnrgTrnfTypFD5Vld.SendCANR_HVCMSSlfEnrgTrnfTypFD5Vld
            OUT_SendCANR_HVCMS_SeldPymntOptnFD5_SendCANR_HVCMS_SeldPymntOptnFD5: accessed-variable=SendCANR_HVCMS_SeldPymntOptnFD5.SendCANR_HVCMS_SeldPymntOptnFD5
            OUT_SendCANR_HVCMS_SeldPymntOptnFD5Vld_SendCANR_HVCMS_SeldPymntOptnFD5Vld: accessed-variable=SendCANR_HVCMS_SeldPymntOptnFD5Vld.SendCANR_HVCMS_SeldPymntOptnFD5Vld
            OUT_SendCANR_HVCMSSelectedServIdFD5_SendCANR_HVCMSSelectedServIdFD5: accessed-variable=SendCANR_HVCMSSelectedServIdFD5.SendCANR_HVCMSSelectedServIdFD5
            OUT_SendCANR_HVCMSSelectedServIdFD5Vld_SendCANR_HVCMSSelectedServIdFD5Vld: accessed-variable=SendCANR_HVCMSSelectedServIdFD5Vld.SendCANR_HVCMSSelectedServIdFD5Vld
            OUT_SendCANR_HVCMSServiceCatgoryFD5_SendCANR_HVCMSServiceCatgoryFD5: accessed-variable=SendCANR_HVCMSServiceCatgoryFD5.SendCANR_HVCMSServiceCatgoryFD5
            OUT_SendCANR_HVCMSServiceCatgoryFD5Vld_SendCANR_HVCMSServiceCatgoryFD5Vld: accessed-variable=SendCANR_HVCMSServiceCatgoryFD5Vld.SendCANR_HVCMSServiceCatgoryFD5Vld
            OUT_SendCANR_HVCMS_ServiceScope_FD5_SendCANR_HVCMS_ServiceScope_FD5: accessed-variable=SendCANR_HVCMS_ServiceScope_FD5.SendCANR_HVCMS_ServiceScope_FD5, variation-point={short-label=vpOUT_SendCANR_HVCMS_ServiceScope_FD5_SendCANR_HVCMS_ServiceScope_FD5, sw-syscond=1}
            OUT_SendCANR_HVCMS_ServiceScope_FD5Vld_SendCANR_HVCMS_ServiceScope_FD5Vld: accessed-variable=SendCANR_HVCMS_ServiceScope_FD5Vld.SendCANR_HVCMS_ServiceScope_FD5Vld, variation-point={short-label=vpOUT_SendCANR_HVCMS_ServiceScope_FD5Vld_SendCANR_HVCMS_ServiceScope_FD5Vld, sw-syscond=1}
            OUT_SendCANR_VDCM_BattBulkSOC_FD5_SendCANR_VDCM_BattBulkSOC_FD5: accessed-variable=SendCANR_VDCM_BattBulkSOC_FD5.SendCANR_VDCM_BattBulkSOC_FD5, variation-point={short-label=vpOUT_SendCANR_VDCM_BattBulkSOC_FD5_SendCANR_VDCM_BattBulkSOC_FD5, sw-syscond=1}
            OUT_SendCANR_VDCM_BattBulkSOC_FD5Vld_SendCANR_VDCM_BattBulkSOC_FD5Vld: accessed-variable=SendCANR_VDCM_BattBulkSOC_FD5Vld.SendCANR_VDCM_BattBulkSOC_FD5Vld, variation-point={short-label=vpOUT_SendCANR_VDCM_BattBulkSOC_FD5Vld_SendCANR_VDCM_BattBulkSOC_FD5Vld, sw-syscond=1}
            OUT_SendCANR_T4_Sensor_Temp_FD5_SendCANR_T4_Sensor_Temp_FD5: accessed-variable=SendCANR_T4_Sensor_Temp_FD5.SendCANR_T4_Sensor_Temp_FD5
            OUT_SendCANR_T4_Sensor_Temp_FD5Vld_SendCANR_T4_Sensor_Temp_FD5Vld: accessed-variable=SendCANR_T4_Sensor_Temp_FD5Vld.SendCANR_T4_Sensor_Temp_FD5Vld
            OUT_SendCANR_T7_CoolantTmpVldty_FD5_SendCANR_T7_CoolantTmpVldty_FD5: accessed-variable=SendCANR_T7_CoolantTmpVldty_FD5.SendCANR_T7_CoolantTmpVldty_FD5
            OUT_SendCANR_T7_CoolantTmpVldty_FD5Vld_SendCANR_T7_CoolantTmpVldty_FD5Vld: accessed-variable=SendCANR_T7_CoolantTmpVldty_FD5Vld.SendCANR_T7_CoolantTmpVldty_FD5Vld
            OUT_SendCANR_T7_Sensor_Temp_FD5_SendCANR_T7_Sensor_Temp_FD5: accessed-variable=SendCANR_T7_Sensor_Temp_FD5.SendCANR_T7_Sensor_Temp_FD5
            OUT_SendCANR_T7_Sensor_Temp_FD5Vld_SendCANR_T7_Sensor_Temp_FD5Vld: accessed-variable=SendCANR_T7_Sensor_Temp_FD5Vld.SendCANR_T7_Sensor_Temp_FD5Vld
      variation point proxy VrntCT5B_HVCMSServiceScope_OBCRdServiceScope: category=CONDITION, condition-access=1
      variation point proxy VrntCT5B_VDCMBattBulkSOC_IDCRPctBattBulkSOC: category=CONDITION, condition-access=1
